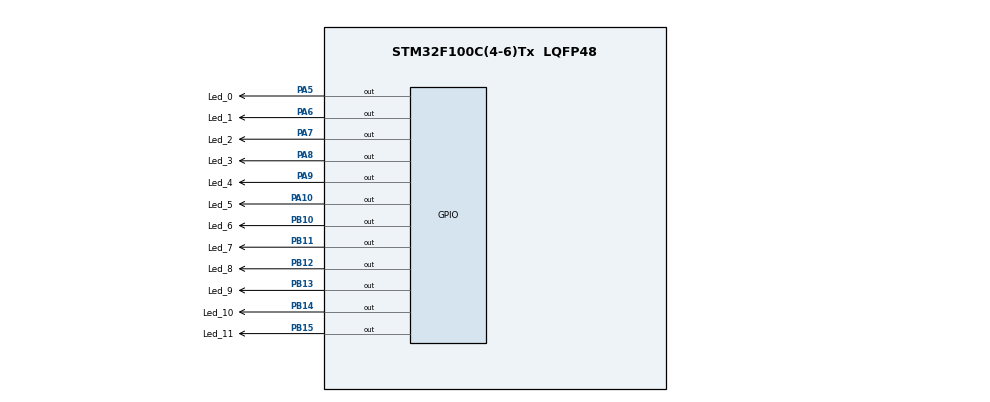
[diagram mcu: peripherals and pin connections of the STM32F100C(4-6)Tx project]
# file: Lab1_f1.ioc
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Mcu.Family=STM32F1
Mcu.Name=STM32F100C(4-6)Tx
Mcu.Package=LQFP48
NVIC.PriorityGroup=NVIC_PRIORITYGROUP_4
NVIC.TIM2_IRQn=true\:0\:0\:false\:false\:true\:true\:true\:true
PA10.GPIO_Label=Led_5
PA10.Signal=GPIO_Output
PA13.Mode=Serial_Wire
PA13.Signal=SYS_JTMS-SWDIO
PA14.Mode=Serial_Wire
PA14.Signal=SYS_JTCK-SWCLK
PA5.GPIO_Label=Led_0
PA5.Signal=GPIO_Output
PA6.GPIO_Label=Led_1
PA6.Signal=GPIO_Output
PA7.GPIO_Label=Led_2
PA7.Signal=GPIO_Output
PA8.GPIO_Label=Led_3
PA8.Signal=GPIO_Output
PA9.GPIO_Label=Led_4
PA9.Signal=GPIO_Output
PB10.GPIO_Label=Led_6
PB10.Signal=GPIO_Output
PB11.GPIO_Label=Led_7
PB11.Signal=GPIO_Output
PB12.GPIO_Label=Led_8
PB12.Signal=GPIO_Output
PB13.GPIO_Label=Led_9
PB13.Signal=GPIO_Output
PB14.GPIO_Label=Led_10
PB14.Signal=GPIO_Output
PB15.GPIO_Label=Led_11
PB15.Signal=GPIO_Output
ProjectManager.HeapSize=0x200
ProjectManager.StackSize=0x400
ProjectManager.TargetToolchain=STM32CubeIDE
RCC.APB1Freq_Value=8000000
RCC.APB2Freq_Value=8000000
TIM2.Period=9
TIM2.Prescaler=7999
VP_TIM2_VS_ClockSourceINT.Mode=Internal
board=custom

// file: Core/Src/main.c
/* USER CODE BEGIN Header */
/**
  ******************************************************************************
  * @file           : main.c
  * @brief          : Main program body
  ******************************************************************************
  * @attention
  *
  * Copyright (c) 2024 STMicroelectronics.
  * All rights reserved.
  *
  * This software is licensed under terms that can be found in the LICENSE file
  * in the root directory of this software component.
  * If no LICENSE file comes with this software, it is provided AS-IS.
  *
  ******************************************************************************
  */
/* USER CODE END Header */
#include "main.h"

/* USER CODE BEGIN Includes */
#include "Lab1.h"
/* USER CODE END Includes */

TIM_HandleTypeDef htim2;

void SystemClock_Config(void);
static void MX_GPIO_Init(void);
static void MX_TIM2_Init(void);

int main(void)
{

  /* MCU Configuration--------------------------------------------------------*/

  /* Reset of all peripherals, Initializes the Flash interface and the Systick. */
  HAL_Init();

  /* Configure the system clock */
  SystemClock_Config();

  /* Initialize all configured peripherals */
  MX_GPIO_Init();
  MX_TIM2_Init();
  /* USER CODE BEGIN 2 */
  System_init_Lab1();
  /* USER CODE END 2 */

  /* Infinite loop */
  /* USER CODE BEGIN WHILE */
  int count = 0;
  int condition = 1;
  while (1)
  {
    /* USER CODE END WHILE */

    /* USER CODE BEGIN 3 */
	  Clock_digital();

  }
  /* USER CODE END 3 */
}

void SystemClock_Config(void)
{
  RCC_OscInitTypeDef RCC_OscInitStruct = {0};
  RCC_ClkInitTypeDef RCC_ClkInitStruct = {0};

  /** Initializes the RCC Oscillators according to the specified parameters
  * in the RCC_OscInitTypeDef structure.
  */
  RCC_OscInitStruct.OscillatorType = RCC_OSCILLATORTYPE_HSI;
  RCC_OscInitStruct.HSIState = RCC_HSI_ON;
  RCC_OscInitStruct.HSICalibrationValue = RCC_HSICALIBRATION_DEFAULT;
  RCC_OscInitStruct.PLL.PLLState = RCC_PLL_NONE;
  if (HAL_RCC_OscConfig(&RCC_OscInitStruct) != HAL_OK)
  {
    Error_Handler();
  }

  /** Initializes the CPU, AHB and APB buses clocks
  */
  RCC_ClkInitStruct.ClockType = RCC_CLOCKTYPE_HCLK|RCC_CLOCKTYPE_SYSCLK
                              |RCC_CLOCKTYPE_PCLK1|RCC_CLOCKTYPE_PCLK2;
  RCC_ClkInitStruct.SYSCLKSource = RCC_SYSCLKSOURCE_HSI;
  RCC_ClkInitStruct.AHBCLKDivider = RCC_SYSCLK_DIV1;
  RCC_ClkInitStruct.APB1CLKDivider = RCC_HCLK_DIV1;
  RCC_ClkInitStruct.APB2CLKDivider = RCC_HCLK_DIV1;

  if (HAL_RCC_ClockConfig(&RCC_ClkInitStruct, FLASH_LATENCY_0) != HAL_OK)
  {
    Error_Handler();
  }
}

static void MX_TIM2_Init(void)
{

  TIM_ClockConfigTypeDef sClockSourceConfig = {0};
  TIM_MasterConfigTypeDef sMasterConfig = {0};

  htim2.Instance = TIM2;
  htim2.Init.Prescaler = 7999;
  htim2.Init.CounterMode = TIM_COUNTERMODE_UP;
  htim2.Init.Period = 9;
  htim2.Init.ClockDivision = TIM_CLOCKDIVISION_DIV1;
  htim2.Init.AutoReloadPreload = TIM_AUTORELOAD_PRELOAD_DISABLE;
  if (HAL_TIM_Base_Init(&htim2) != HAL_OK)
  {
    Error_Handler();
  }
  sClockSourceConfig.ClockSource = TIM_CLOCKSOURCE_INTERNAL;
  if (HAL_TIM_ConfigClockSource(&htim2, &sClockSourceConfig) != HAL_OK)
  {
    Error_Handler();
  }
  sMasterConfig.MasterOutputTrigger = TIM_TRGO_RESET;
  sMasterConfig.MasterSlaveMode = TIM_MASTERSLAVEMODE_DISABLE;
  if (HAL_TIMEx_MasterConfigSynchronization(&htim2, &sMasterConfig) != HAL_OK)
  {
    Error_Handler();
  }

}

static void MX_GPIO_Init(void)
{
  GPIO_InitTypeDef GPIO_InitStruct = {0};

  /* GPIO Ports Clock Enable */
  __HAL_RCC_GPIOA_CLK_ENABLE();
  __HAL_RCC_GPIOB_CLK_ENABLE();

  /*Configure GPIO pin Output Level */
  HAL_GPIO_WritePin(GPIOA, Led_0_Pin|Led_1_Pin|Led_2_Pin|Led_3_Pin
                          |Led_4_Pin|Led_5_Pin, GPIO_PIN_RESET);

  /*Configure GPIO pin Output Level */
  HAL_GPIO_WritePin(GPIOB, Led_6_Pin|Led_7_Pin|Led_8_Pin|Led_9_Pin
                          |Led_10_Pin|Led_11_Pin, GPIO_PIN_RESET);

  /*Configure GPIO pins : Led_0_Pin Led_1_Pin Led_2_Pin Led_3_Pin
                           Led_4_Pin Led_5_Pin */
  GPIO_InitStruct.Pin = Led_0_Pin|Led_1_Pin|Led_2_Pin|Led_3_Pin
                          |Led_4_Pin|Led_5_Pin;
  GPIO_InitStruct.Mode = GPIO_MODE_OUTPUT_PP;
  GPIO_InitStruct.Pull = GPIO_NOPULL;
  GPIO_InitStruct.Speed = GPIO_SPEED_FREQ_LOW;
  HAL_GPIO_Init(GPIOA, &GPIO_InitStruct);

  /*Configure GPIO pins : Led_6_Pin Led_7_Pin Led_8_Pin Led_9_Pin
                           Led_10_Pin Led_11_Pin */
  GPIO_InitStruct.Pin = Led_6_Pin|Led_7_Pin|Led_8_Pin|Led_9_Pin
                          |Led_10_Pin|Led_11_Pin;
  GPIO_InitStruct.Mode = GPIO_MODE_OUTPUT_PP;
  GPIO_InitStruct.Pull = GPIO_NOPULL;
  GPIO_InitStruct.Speed = GPIO_SPEED_FREQ_LOW;
  HAL_GPIO_Init(GPIOB, &GPIO_InitStruct);

}

void Error_Handler(void)
{
  __disable_irq();
  while (1)
  {
  }
}
